# ATmega8535 device description
Architecture: AVR8; Family: megaAVR
Programming and debug interfaces: ISP, HVPP
Registers are 8-bit, access not given, no defined reset value unless marked. A register's access mark holds for its fields unless they carry their own. Offsets are from the block's base; lines under a group give offsets from that group; [hi:lo] are bit positions; {n}, {i} and the like mark numbered series; 'fields as' and 'values as' point back to an identical list; <NAME> marks a mode.

## Ordering variants
standard: 2.7 to 5.5 V

## Memory
prog space: start 0x0000 size 0x2000, little endian
  0x0000 FLASH size 0x2000 flash, rw, executable, page 0x40
  0x1f00 BOOT_SECTION_1 size 0x0100 flash, rw, executable, page 0x40
  0x1e00 BOOT_SECTION_2 size 0x0200 flash, rw, executable, page 0x40
  0x1c00 BOOT_SECTION_3 size 0x0400 flash, rw, executable, page 0x40
  0x1800 BOOT_SECTION_4 size 0x0800 flash, rw, executable, page 0x40
signatures space: start 0 size 3, little endian
  0 SIGNATURES size 3 signatures, ro
fuses space: start 0 size 0x0002, little endian
  0 FUSES size 0x0002 fuses, rw
lockbits space: start 0 size 0x0001, little endian
  0 LOCKBITS size 0x0001 lockbits, rw
data space: start 0x0000 size 0x0260, little endian
  0x0000 REGISTERS size 0x0020 regs
  0x0020 MAPPED_IO size 0x0040 io
  0x0060 IRAM size 0x0200 ram
eeprom space: start 0x0000 size 0x0200, little endian
  0x0000 EEPROM size 0x0200 eeprom, rw, page 0x04
io space: start 0x00 size 0x40, little endian
osccal space: start 0 size 4, little endian
  0 OSCCAL size 4 osccal, ro

## Peripheral instances (address, pins/pin function, parameters)
ADC at 0x00 — Analog-to-Digital Converter
AC at 0x00 — Analog Comparator
TWI at 0x00 — Two Wire Serial Interface
USART at 0x00
PORTA at 0x00 — I/O Port
PORTB at 0x00 — I/O Port
PORTC at 0x00 — I/O Port
PORTD at 0x00 — I/O Port
SPI at 0x00 — Serial Peripheral Interface
EEPROM at 0x00
TC0 at 0x00 — Timer/Counter, 8-bit
TC1 at 0x00 — Timer/Counter, 16-bit
TC2 at 0x00 — Timer/Counter, 8-bit Async
EXINT at 0x00 — External Interrupts
WDT at 0x00 — Watchdog Timer
CPU at 0x00 — CPU Registers
  parameters: CORE_VERSION=V2E
FUSE at 0 in fuses — Fuses
LOCKBIT at 0 in lockbits — Lockbits

## Interrupts
0 RESET — External Reset, Power-on Reset and Watchdog Reset
1 INT0 — External Interrupt 0
2 INT1 — External Interrupt 1
3 TIMER2_COMP — Timer/Counter2 Compare Match
4 TIMER2_OVF — Timer/Counter2 Overflow
5 TIMER1_CAPT — Timer/Counter1 Capture Event
6 TIMER1_COMPA — Timer/Counter1 Compare Match A
7 TIMER1_COMPB — Timer/Counter1 Compare Match B
8 TIMER1_OVF — Timer/Counter1 Overflow
9 TIMER0_OVF — Timer/Counter0 Overflow
10 SPI_STC — SPI Serial Transfer Complete
11 USART_RX — USART, RX Complete
12 USART_UDRE — USART Data Register Empty
13 USART_TX — USART, TX Complete
14 ADC — ADC Conversion Complete
15 EE_RDY — EEPROM Ready
16 ANA_COMP — Analog Comparator
17 TWI — Two-wire Serial Interface
18 INT2 — External Interrupt Request 2
19 TIMER0_COMP — TimerCounter0 Compare Match
20 SPM_RDY — Store Program Memory Read

## Properties
SIGNATURES: SIGNATURE0=0x1e, SIGNATURE1=0x93, SIGNATURE2=0x08

## LOCKBIT — Lockbits
Instances: LOCKBIT 0 in lockbits
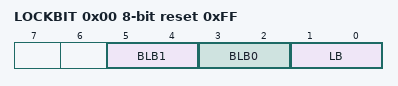
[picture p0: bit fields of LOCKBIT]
0x00 LOCKBIT reset 0xFF
  [5:4] BLB1 — Boot Loader Protection Mode
    0=LPM_SPM_DISABLE (LPM and SPM prohibited in Boot Section); 1=LPM_DISABLE (LPM prohibited in Boot Section); 2=SPM_DISABLE (SPM prohibited in Boot Section); 3=NO_LOCK (No lock on SPM and LPM in Boot Section)
  [3:2] BLB0 — Boot Loader Protection Mode
    0=LPM_SPM_DISABLE (LPM and SPM prohibited in Application Section); 1=LPM_DISABLE (LPM prohibited in Application Section); 2=SPM_DISABLE (SPM prohibited in Application Section); 3=NO_LOCK (No lock on SPM and LPM in Application Section)
  [1:0] LB — Memory Lock
    0=PROG_VER_DISABLED (Further programming and verification disabled); 2=PROG_DISABLED (Further programming disabled); 3=NO_LOCK (No memory lock features enabled)

## ADC — Analog-to-Digital Converter
Instances: ADC 0x00
0x24 ADC 16-bit — ADC Data Register Bytes
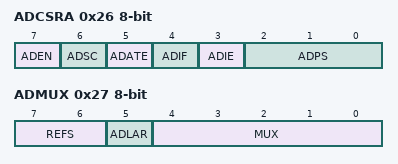
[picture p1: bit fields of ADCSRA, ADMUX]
0x26 ADCSRA — The ADC Control and Status register
  [7] ADEN — ADC Enable
  [6] ADSC — ADC Start Conversion
  [5] ADATE — ADC Auto Trigger
  [4] ADIF — ADC Interrupt Flag
  [3] ADIE — ADC Interrupt Enable
  [2:0] ADPS — ADC Prescaler Select Bits
    0=2; 1=2; 2=4; 3=8; 4=16; 5=32; 6=64; 7=128
0x27 ADMUX — The ADC multiplexer Selection Register
  [7:6] REFS — Reference Selection Bits
    0=AREF, Internal Vref turned off; 1=AVCC with external capacitor at AREF pin; 3=Internal 2.56V Voltage Reference with external capacitor at AREF pin
  [5] ADLAR — Left Adjust Result
  [4:0] MUX — Analog Channel and Gain Selection Bits
0x50 SFIOR — Special Function IO Register
  [7:5] ADTS — ADC Auto Trigger Sources
